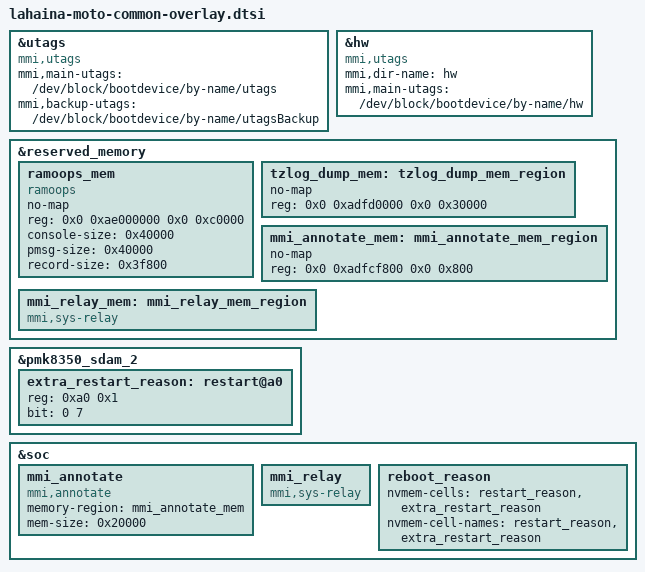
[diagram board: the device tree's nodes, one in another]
/* Copyright (c) 2020, The Linux Foundation. All rights reserved.
 *
 * This program is free software; you can redistribute it and/or modify
 * it under the terms of the GNU General Public License version 2 and
 * only version 2 as published by the Free Software Foundation.
 *
 * This program is distributed in the hope that it will be useful,
 * but WITHOUT ANY WARRANTY; without even the implied warranty of
 * MERCHANTABILITY or FITNESS FOR A PARTICULAR PURPOSE.  See the
 * GNU General Public License for more details.
 */

#include "lahaina-moto-common-overlay-base.dtsi"
#include "carrier-channel-ids.dtsi"

&utags {
	compatible = "mmi,utags";
	mmi,main-utags = "/dev/block/bootdevice/by-name/utags";
	mmi,backup-utags = "/dev/block/bootdevice/by-name/utagsBackup";
};

&hw {
	compatible = "mmi,utags";
	mmi,dir-name = "hw";
	mmi,main-utags = "/dev/block/bootdevice/by-name/hw";
};

&reserved_memory{
	ramoops_mem {
		compatible = "ramoops";
		no-map;
		reg = <0x0 0xae000000 0x0 0xc0000>;
		console-size = <0x40000>;
		pmsg-size = <0x40000>;
		record-size = <0x3f800>;
	};

	tzlog_dump_mem: tzlog_dump_mem_region {
			no-map;
			reg = <0x0 0xadfd0000 0x0 0x30000>;
	};

	mmi_annotate_mem: mmi_annotate_mem_region {
			  no-map;
			  reg = <0x0 0xadfcf800 0x0 0x800>;
	};

	mmi_relay_mem: mmi_relay_mem_region {
			  compatible = "mmi,sys-relay";
	};
};

&pmk8350_sdam_2 {
	extra_restart_reason:restart@a0 {
		reg = <0xa0 0x1>;
		bit = <0 7>;
	};
};

&soc {
	mmi_annotate {
		compatible = "mmi,annotate";
		memory-region = <&mmi_annotate_mem>;
		mem-size = <0x20000>;
	};

	mmi_relay{
		compatible = "mmi,sys-relay";
	};

	reboot_reason {
		nvmem-cells = <&restart_reason>, <&extra_restart_reason>;
		nvmem-cell-names = "restart_reason", "extra_restart_reason";
	};
};

